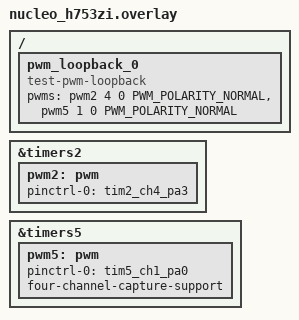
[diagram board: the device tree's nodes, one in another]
/*
 * Copyright (c) 2025 STMicroelectronics
 *
 * SPDX-License-Identifier: Apache-2.0
 */


/* PWM pins connection :
 *
 *  Perih   Pin   Hdr
 *  pwm2    PA3  CN9:1
 *  pwm5    PA0  CN10:29
 *
 * Short Pin PA3 to PA0, for the test to pass.
 */

#include <zephyr/dt-bindings/pwm/pwm.h>

/ {
	pwm_loopback_0 {
		compatible = "test-pwm-loopback";
		/* first index must be a 32-Bit timer */
		pwms = <&pwm2 4 0 PWM_POLARITY_NORMAL>,
		       <&pwm5 1 0 PWM_POLARITY_NORMAL>;
	};
};

/* 32-Bit timers */
&timers2 {
	status = "okay";

	pwm2: pwm {
		status = "okay";
		pinctrl-0 = <&tim2_ch4_pa3>; /* CN9 PIN1 A0 */
		pinctrl-names = "default";
	};
};

&timers5 {
	status = "okay";

	pwm5: pwm {
		status = "okay";
		pinctrl-0 = <&tim5_ch1_pa0>; /* CN10 PIN29 */
		pinctrl-names = "default";

		/* At least one of the test devices need to verify
		 * the four-channel-capture-support in this test.
		 */
		four-channel-capture-support;
	};
};
